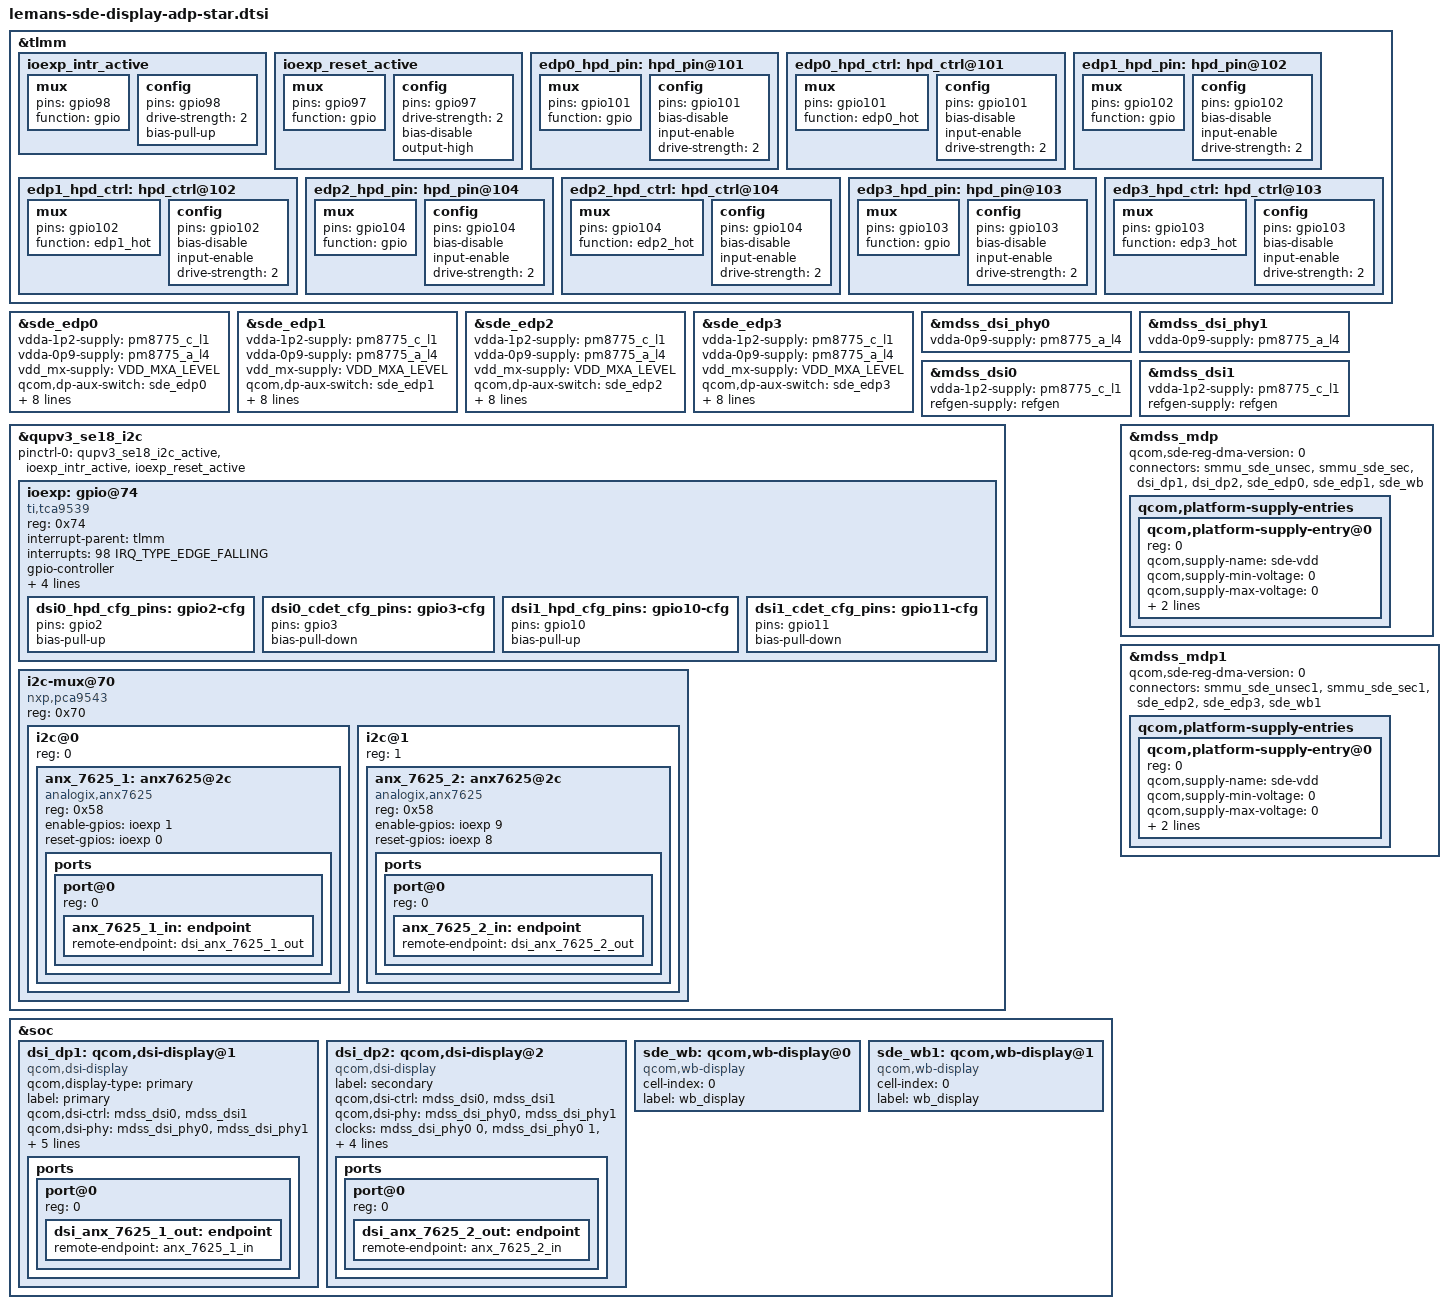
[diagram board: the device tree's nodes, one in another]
#include <dt-bindings/clock/qcom,rpmh.h>
#include "lemans-sde.dtsi"

&tlmm {
	ioexp_intr_active: ioexp_intr_active {
		mux {
			pins = "gpio98";
			function = "gpio";
		};
		config {
			pins = "gpio98";
			drive-strength = <2>;
			bias-pull-up;
		};
	};

	ioexp_reset_active: ioexp_reset_active {
		mux {
			pins = "gpio97";
			function = "gpio";
		};
		config {
			pins = "gpio97";
			drive-strength = <2>;
			bias-disable;
			output-high;
		};
	};

	edp0_hpd_pin: hpd_pin@101 {
		mux {
			pins = "gpio101";
			function = "gpio";
		};

		config {
			pins = "gpio101";
			bias-disable;
			input-enable;
			drive-strength = <2>;
		};
	};

	edp0_hpd_ctrl: hpd_ctrl@101 {
		mux {
			pins = "gpio101";
			function = "edp0_hot";
		};

		config {
			pins = "gpio101";
			bias-disable;
			input-enable;
			drive-strength = <2>;
		};
	};

	edp1_hpd_pin: hpd_pin@102 {
		mux {
			pins = "gpio102";
			function = "gpio";
		};

		config {
			pins = "gpio102";
			bias-disable;
			input-enable;
			drive-strength = <2>;
		};
	};

	edp1_hpd_ctrl: hpd_ctrl@102 {
		mux {
			pins = "gpio102";
			function = "edp1_hot";
		};

		config {
			pins = "gpio102";
			bias-disable;
			input-enable;
			drive-strength = <2>;
		};
	};

	edp2_hpd_pin: hpd_pin@104 {
		mux {
			pins = "gpio104";
			function = "gpio";
		};

		config {
			pins = "gpio104";
			bias-disable;
			input-enable;
			drive-strength = <2>;
		};
	};

	edp2_hpd_ctrl: hpd_ctrl@104 {
		mux {
			pins = "gpio104";
			function = "edp2_hot";
		};

		config {
			pins = "gpio104";
			bias-disable;
			input-enable;
			drive-strength = <2>;
		};
	};

	edp3_hpd_pin: hpd_pin@103 {
		mux {
			pins = "gpio103";
			function = "gpio";
		};

		config {
			pins = "gpio103";
			bias-disable;
			input-enable;
			drive-strength = <2>;
		};
	};

	edp3_hpd_ctrl: hpd_ctrl@103 {
		mux {
			pins = "gpio103";
			function = "edp3_hot";
		};

		config {
			pins = "gpio103";
			bias-disable;
			input-enable;
			drive-strength = <2>;
		};
	};

};

&sde_edp0 {
	vdda-1p2-supply = <&pm8775_c_l1>;
	vdda-0p9-supply = <&pm8775_a_l4>;
	vdd_mx-supply = <&VDD_MXA_LEVEL>;

	qcom,dp-aux-switch = <&sde_edp0>;
	qcom,dp-hpd-gpio = <&tlmm 101 0>;
	qcom,mst-fixed-topology-ports = <1 2>;
	qcom,dp-low-power-hw-hpd;
	pinctrl-names = "mdss_dp_hpd_active", "mdss_dp_hpd_tlmm", "mdss_dp_hpd_ctrl",
			"mdss_dp_active", "mdss_dp_sleep";
	pinctrl-0 = <&edp0_hpd_pin>;
	pinctrl-1 = <&edp0_hpd_pin>;
	pinctrl-2 = <&edp0_hpd_ctrl>;
	pinctrl-3 = <&edp0_hpd_ctrl>;
	pinctrl-4 = <&edp0_hpd_pin>;
};

&sde_edp1 {
	vdda-1p2-supply = <&pm8775_c_l1>;
	vdda-0p9-supply = <&pm8775_a_l4>;
	vdd_mx-supply = <&VDD_MXA_LEVEL>;

	qcom,dp-aux-switch = <&sde_edp1>;
	qcom,dp-hpd-gpio = <&tlmm 102 0>;
	qcom,mst-fixed-topology-ports = <1 2>;
	qcom,dp-low-power-hw-hpd;
	pinctrl-names = "mdss_dp_hpd_active", "mdss_dp_hpd_tlmm", "mdss_dp_hpd_ctrl",
			"mdss_dp_active", "mdss_dp_sleep";
	pinctrl-0 = <&edp1_hpd_pin>;
	pinctrl-1 = <&edp1_hpd_pin>;
	pinctrl-2 = <&edp1_hpd_ctrl>;
	pinctrl-3 = <&edp1_hpd_ctrl>;
	pinctrl-4 = <&edp1_hpd_pin>;
};

&sde_edp2 {
	vdda-1p2-supply = <&pm8775_c_l1>;
	vdda-0p9-supply = <&pm8775_a_l4>;
	vdd_mx-supply = <&VDD_MXA_LEVEL>;

	qcom,dp-aux-switch = <&sde_edp2>;
	qcom,dp-hpd-gpio = <&tlmm 104 0>;
	qcom,mst-fixed-topology-ports = <1 2>;
	qcom,dp-low-power-hw-hpd;
	pinctrl-names = "mdss_dp_hpd_active", "mdss_dp_hpd_tlmm", "mdss_dp_hpd_ctrl",
			"mdss_dp_active", "mdss_dp_sleep";
	pinctrl-0 = <&edp2_hpd_pin>;
	pinctrl-1 = <&edp2_hpd_pin>;
	pinctrl-2 = <&edp2_hpd_ctrl>;
	pinctrl-3 = <&edp2_hpd_ctrl>;
	pinctrl-4 = <&edp2_hpd_pin>;
};

&sde_edp3 {
	vdda-1p2-supply = <&pm8775_c_l1>;
	vdda-0p9-supply = <&pm8775_a_l4>;
	vdd_mx-supply = <&VDD_MXA_LEVEL>;

	qcom,dp-aux-switch = <&sde_edp3>;
	qcom,dp-hpd-gpio = <&tlmm 103 0>;
	qcom,mst-fixed-topology-ports = <1 2>;
	qcom,dp-low-power-hw-hpd;
	pinctrl-names = "mdss_dp_hpd_active", "mdss_dp_hpd_tlmm", "mdss_dp_hpd_ctrl",
			"mdss_dp_active", "mdss_dp_sleep";
	pinctrl-0 = <&edp3_hpd_pin>;
	pinctrl-1 = <&edp3_hpd_pin>;
	pinctrl-2 = <&edp3_hpd_ctrl>;
	pinctrl-3 = <&edp3_hpd_ctrl>;
	pinctrl-4 = <&edp3_hpd_pin>;
};

&mdss_dsi_phy0 {
	vdda-0p9-supply = <&pm8775_a_l4>;
};

&mdss_dsi_phy1 {
	vdda-0p9-supply = <&pm8775_a_l4>;
};

&mdss_dsi0 {
	vdda-1p2-supply = <&pm8775_c_l1>;
	refgen-supply = <&refgen>;
};

&mdss_dsi1 {
	vdda-1p2-supply = <&pm8775_c_l1>;
	refgen-supply = <&refgen>;
};

&qupv3_se18_i2c {
	#address-cells = <1>;
	#size-cells = <0>;

	status = "ok";

	pinctrl-0 = <&qupv3_se18_i2c_active
		&ioexp_intr_active
		&ioexp_reset_active>;

	ioexp: gpio@74 {
		#gpio-cells = <2>;
		#interrupt-cells = <2>;
		compatible = "ti,tca9539";
		reg = <0x74>;
		interrupt-parent = <&tlmm>;
		interrupts = <98 IRQ_TYPE_EDGE_FALLING>;
		gpio-controller;
		interrupt-controller;

		pinctrl-names = "default";
		pinctrl-0 = <
			&dsi0_hpd_cfg_pins
			&dsi0_cdet_cfg_pins
			&dsi1_hpd_cfg_pins
			&dsi1_cdet_cfg_pins
			>;

		dsi0_hpd_cfg_pins: gpio2-cfg {
			pins = "gpio2";
			bias-pull-up;
		};

		dsi0_cdet_cfg_pins: gpio3-cfg {
			pins = "gpio3";
			bias-pull-down;
		};

		dsi1_hpd_cfg_pins: gpio10-cfg {
			pins = "gpio10";
			bias-pull-up;
		};

		dsi1_cdet_cfg_pins: gpio11-cfg {
			pins = "gpio11";
			bias-pull-down;
		};
	};

	i2c-mux@70 {
		compatible = "nxp,pca9543";
		reg = <0x70>;
		#address-cells = <1>;
		#size-cells = <0>;

		i2c@0 {
			reg = <0>;
			#address-cells = <1>;
			#size-cells = <0>;

			anx_7625_1: anx7625@2c {
				compatible = "analogix,anx7625";
				reg = <0x58>;
				enable-gpios = <&ioexp 1 0>;
				reset-gpios = <&ioexp 0 0>;
			};
		};

		i2c@1 {
			reg = <1>;
			#address-cells = <1>;
			#size-cells = <0>;

			anx_7625_2: anx7625@2c {
				compatible = "analogix,anx7625";
				reg = <0x58>;
				enable-gpios = <&ioexp 9 0>;
				reset-gpios = <&ioexp 8 0>;
			};
		};
	};
};

&anx_7625_1 {
	ports {
		#address-cells = <1>;
		#size-cells = <0>;

		port@0 {
			reg = <0>;
			anx_7625_1_in: endpoint {
				remote-endpoint = <&dsi_anx_7625_1_out>;
			};
		};
	};
};

&anx_7625_2 {
	ports {
		#address-cells = <1>;
		#size-cells = <0>;

		port@0 {
			reg = <0>;
			anx_7625_2_in: endpoint {
				remote-endpoint = <&dsi_anx_7625_2_out>;
			};
		};
	};
};

#include "dsi-panel-ext-bridge-1080p-gen3.dtsi"

&soc {
	#address-cells = <1>;
	#size-cells = <1>;

	dsi_dp1: qcom,dsi-display@1 {
		compatible = "qcom,dsi-display";
                qcom,display-type = "primary";
		label = "primary";

		qcom,dsi-ctrl = <&mdss_dsi0 &mdss_dsi1>;
		qcom,dsi-phy = <&mdss_dsi_phy0 &mdss_dsi_phy1>;

		clocks = <&mdss_dsi_phy0 0>,
			<&mdss_dsi_phy0 1>,
			<&mdss_dsi_phy1 2>,
			<&mdss_dsi_phy1 3>;
		clock-names = "pll_byte_clk0", "pll_dsi_clk0",
			"pll_byte_clk1", "pll_dsi_clk1";

		qcom,mdp = <&mdss_mdp>;
		qcom,dsi-default-panel = <&dsi_ext_bridge_1080p>;
		qcom,panel-te-source = <0>;

		ports {
			#address-cells = <1>;
			#size-cells = <0>;

			port@0 {
				reg = <0>;
				dsi_anx_7625_1_out: endpoint {
					remote-endpoint = <&anx_7625_1_in>;
				};
			};
		};
	};

	dsi_dp2: qcom,dsi-display@2 {
		compatible = "qcom,dsi-display";
		label = "secondary";

		qcom,dsi-ctrl = <&mdss_dsi0 &mdss_dsi1>;
		qcom,dsi-phy = <&mdss_dsi_phy0 &mdss_dsi_phy1>;

		clocks = <&mdss_dsi_phy0 0>,
			<&mdss_dsi_phy0 1>,
			<&mdss_dsi_phy1 2>,
			<&mdss_dsi_phy1 3>;
		clock-names = "pll_byte_clk0", "pll_dsi_clk0",
			"pll_byte_clk1", "pll_dsi_clk1";

		qcom,mdp = <&mdss_mdp>;
		qcom,dsi-default-panel = <&dsi_ext_bridge_1080p>;
		qcom,panel-te-source = <1>;

		ports {
			#address-cells = <1>;
			#size-cells = <0>;

			port@0 {
				reg = <0>;
				dsi_anx_7625_2_out: endpoint {
					remote-endpoint = <&anx_7625_2_in>;
				};
			};
		};
	};

	sde_wb: qcom,wb-display@0 {
		compatible = "qcom,wb-display";
		cell-index = <0>;
		label = "wb_display";
	};

	sde_wb1: qcom,wb-display@1 {
		compatible = "qcom,wb-display";
		cell-index = <0>;
		label = "wb_display";
	};
};

&mdss_mdp {
	qcom,sde-reg-dma-version = <0>;
	connectors = <&smmu_sde_unsec &smmu_sde_sec
			&dsi_dp1 &dsi_dp2
			&sde_edp0 &sde_edp1
			&sde_wb>;

	qcom,platform-supply-entries {
		#address-cells = <1>;
		#size-cells = <0>;

		qcom,platform-supply-entry@0 {
			reg = <0>;
			qcom,supply-name = "sde-vdd";
			qcom,supply-min-voltage = <0>;
			qcom,supply-max-voltage = <0>;
			qcom,supply-enable-load = <0>;
			qcom,supply-disable-load = <0>;
		};
	};
};

&mdss_mdp1 {
	qcom,sde-reg-dma-version = <0>;
	connectors = <&smmu_sde_unsec1 &smmu_sde_sec1
			&sde_edp2 &sde_edp3
			&sde_wb1>;

	qcom,platform-supply-entries {
		#address-cells = <1>;
		#size-cells = <0>;

		qcom,platform-supply-entry@0 {
			reg = <0>;
			qcom,supply-name = "sde-vdd";
			qcom,supply-min-voltage = <0>;
			qcom,supply-max-voltage = <0>;
			qcom,supply-enable-load = <0>;
			qcom,supply-disable-load = <0>;
		};
	};
};
